# CONTROLSS_ADC4_CFG_CONTROLSS_ADC4_CFG register map
Vendor: Texas Instruments
Peripheral module from a debugger description file (folder AM263).
Registers are 16-bit, read-write, reset values left out (the file's numbers can be read two ways) unless marked. A register's access mark holds for its fields unless they carry their own. Offsets are as the file gives them; lines under a group give offsets from that group; [hi:lo] are bit positions; {n}, {i} and the like mark numbered series; 'fields as' and 'values as' point back to an identical list; <NAME> marks a mode.

## CONTROLSS_ADC4_CFG_CONTROLSS_ADC4_CFG
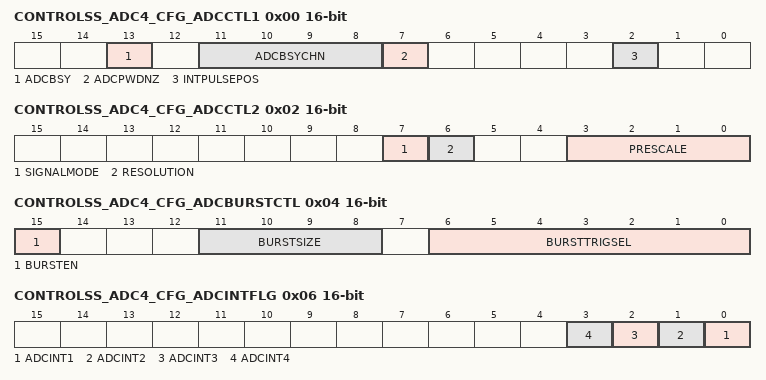
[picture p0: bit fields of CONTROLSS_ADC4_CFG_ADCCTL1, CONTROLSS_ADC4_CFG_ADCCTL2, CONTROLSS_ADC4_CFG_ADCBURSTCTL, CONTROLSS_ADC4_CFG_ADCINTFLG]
0x00 CONTROLSS_ADC4_CFG_ADCCTL1 access per field
  [13] ADCBSY ro — ADC Busy. Set when ADC SOC is generated, cleared by hardware four ADC clocks after negative edge of S/H pulse. Used by the ADC state machine to determine if ADC is available to sample. 0 ADC is available to sample next channel 1 ADC is busy and cannot sample another channel
  [11:8] ADCBSYCHN ro — ADC Busy Channel. Set when an ADC Start of Conversion (SOC) is generated. When ADCBSY=0: holds the value of the last converted SOC When ADCBSY=1: reflects the SOC currently being processed 0h SOC0 is currently processing or was last SOC converted 1h SOC1 is currently processing or was last SOC converted 2h SOC2 is currently processing or was last SOC converted 3h SOC3 is currently processing or was last SOC converted 4h SOC4 is currently processing or was last SOC converted 5h SOC5 is currently processing or was last SOC converted 6h SOC6 is currently processing or was last SOC converted 7h SOC7 is currently processing or was last SOC converted 8h SOC8 is currently processing or was last SOC converted 9h SOC9 is currently processing or was last SOC converted Ah SOC10 is currently processing or was last SOC converted Bh SOC11 is currently processing or was last SOC converted Ch SOC12 is currently processing or was last SOC converted Dh SOC13 is currently processing or was last SOC converted Eh SOC14 is currently processing or was last SOC converted Fh SOC15 is currently processing or was last SOC converted
  [7] ADCPWDNZ rw — ADC Power Down (active low). This bit controls the power up and power down of all the analog circuitry inside the analog core. 0 All analog circuitry inside the core is powered down 1 All analog circuitry inside the core is powered up
  [2] INTPULSEPOS rw — ADC Interrupt Pulse Position. 0 Interrupt pulse generation occurs when ADC begins conversion (at the end of the acquisition window) plus a number of SYSCLK cycles as specified in the ADCINTCYCLE.OFFSET register. 1 Interrupt pulse generation occurs at the end of the conversion, 1 cycle prior to the ADC result latching into its result register
0x02 CONTROLSS_ADC4_CFG_ADCCTL2
  [7] SIGNALMODE — SOC Signaling Mode. Selects the input mode of the converter. Use the AdcSetMode function to change the signal mode. 0 Single-ended 1 Differential
  [6] RESOLUTION — SOC Conversion Resolution. Selects the resolution of the converter. Use the AdcSetMode function to change the resolution. 0 12-bit resolution 1 16-bit resolution
  [3:0] PRESCALE — ADC Clock Prescaler. 0000 ADCCLK = Input Clock / 1.0 0001 Invalid 0010 ADCCLK = Input Clock / 2.0 0011 ADCCLK = Input Clock / 2.5 0100 ADCCLK = Input Clock / 3.0 0101 ADCCLK = Input Clock / 3.5 0110 ADCCLK = Input Clock / 4.0 0111 ADCCLK = Input Clock / 4.5 1000 ADCCLK = Input Clock / 5.0 1001 ADCCLK = Input Clock / 5.5 1010 ADCCLK = Input Clock / 6.0 1011 ADCCLK = Input Clock / 6.5 1100 ADCCLK = Input Clock / 7.0 1101 ADCCLK = Input Clock / 7.5 1110 ADCCLK = Input Clock / 8.0 1111 ADCCLK = Input Clock / 8.5
0x04 CONTROLSS_ADC4_CFG_ADCBURSTCTL
  [15] BURSTEN — SOC Burst Mode Enable. This bit enables the SOC Burst Mode of operation. 0 Burst mode is disabled. 1 Burst mode is enabled.
  [11:8] BURSTSIZE — SOC Burst Size Select. This bit field determines how many SOCs are converted when a burst conversion sequence is started. The first SOC converted is defined by the round robin pointer, which is advanced as each SOC is converted. 0h 1 SOC converted 1h 2 SOCs converted 2h 3 SOCs converted 3h 4 SOCs converted 4h 5 SOCs converted 5h 6 SOCs converted 6h 7 SOCs converted 7h 8 SOCs converted 8h 9 SOCs converted 9h 10 SOCs converted Ah 11 SOCs converted Bh 12 SOCs converted Ch 13 SOCs converted Dh 14 SOCs converted Eh 15 SOCs converted Fh 16 SOCs converted
  [6:0] BURSTTRIGSEL — SOC Burst Trigger Source Select. Configures which trigger will start a burst conversion sequence. 00h - 7Fh: See AM602 spec. for trigger defintion
0x06 CONTROLSS_ADC4_CFG_ADCINTFLG ro
  [n-1] ADCINT{n} (n=1..4) — ADC Interrupt {n} Flag. Reading these flags indicates if the associated ADCINT pulse was generated since the last clear. 0 No ADC interrupt pulse generated 1 ADC interrupt pulse generated If the ADC interrupt is placed in continue to interrupt mode (INTSELxNy register) then further interrupt pulses are generated whenever a selected EOC event occurs even if the flag bit is set. If the continuous mode is not enabled, then no further interrupt pulses are generated until the user clears this flag bit using the ADCINTFLGCLR register. Rather, an ADC interrupt overflow event occurs in the ADCINTOVF register.
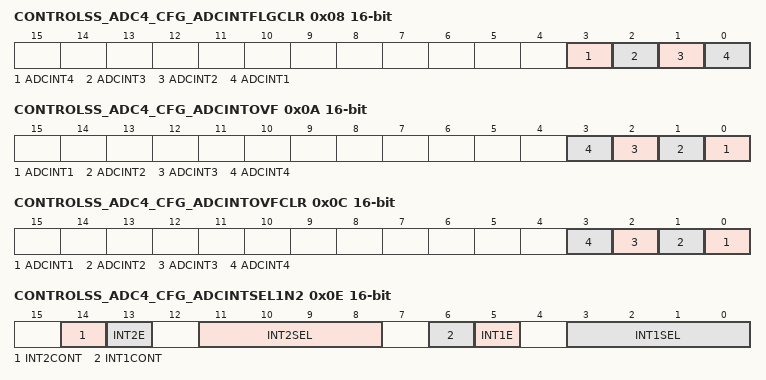
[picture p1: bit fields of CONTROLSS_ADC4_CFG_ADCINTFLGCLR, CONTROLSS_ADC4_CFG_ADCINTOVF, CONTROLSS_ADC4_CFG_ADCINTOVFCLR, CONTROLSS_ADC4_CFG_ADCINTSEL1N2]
0x08 CONTROLSS_ADC4_CFG_ADCINTFLGCLR access not given
  [3] ADCINT4 — ADC Interrupt 4 Flag Clear. Reads return 0. 0 No action 1 Clears ADCINT4 and ADCINT4RESULT flags in the ADCINTFLG register. If software sets the clear bit on the same cycle that hardware is trying to set the flag bit, then hardware has priority and the overflow bit will not be set (access RW RRETURNS0S)
  [2] ADCINT3 — ADC Interrupt 3 Flag Clear. Reads return 0. 0 No action 1 Clears ADCINT3 and ADCINT3RESULT flags in the ADCINTFLG register. If software sets the clear bit on the same cycle that hardware is trying to set the flag bit, then hardware has priority and the overflow bit will not be set (access RW RRETURNS0S)
  [1] ADCINT2 — ADC Interrupt 2 Flag Clear. Reads return 0. 0 No action 1 Clears ADCINT2 and ADCINT2RESULT flags in the ADCINTFLG register. . If software sets the clear bit on the same cycle that hardware is trying to set the flag bit, then hardware has priority and the overflow bit will not be set (access RW RRETURNS0S)
  [0] ADCINT1 — ADC Interrupt 1 Flag Clear. Reads return 0. 0 No action 1 Clears ADCINT1 and ADCINT1RESULT flags in the ADCINTFLG register. If software sets the clear bit on the same cycle that hardware is trying to set the flag bit, then hardware has priority and the overflow bit will not be set (access RW RRETURNS0S)
0x0A CONTROLSS_ADC4_CFG_ADCINTOVF ro
  [n-1] ADCINT{n} (n=1..4) — ADC Interrupt {n} Overflow Flags Indicates if an overflow occurred when generating ADCINT pulses. If the respective ADCINTFLG bit is set and a selected additional EOC trigger is generated, then an overflow condition occurs. 0 No ADC interrupt overflow event detected. 1 ADC Interrupt overflow event detected. The overflow bit does not care about the continuous mode bit state. An overflow condition is generated irrespective of this mode selection.
0x0C CONTROLSS_ADC4_CFG_ADCINTOVFCLR access not given
  [n-1] ADCINT{n} (n=1..4) — ADC Interrupt {n} Overflow Clear Bits 0 No action. 1 Clears the respective overflow bit in the ADCINTOVF register. If software tries to set this bit on the same clock cycle that hardware tries to set the overflow bit in the ADCINTOVF register, then hardware has priority and the ADCINTOVF bit will be set. (access RW RRETURNS0S)
0x0E CONTROLSS_ADC4_CFG_ADCINTSEL1N2
  [14] INT2CONT — ADCINT2 Continue to Interrupt Mode 0 No further ADCINT2 pulses are generated until ADCINT2 flag (in ADCINTFLG register) is cleared by user. 1 ADCINT2 pulses are generated whenever an EOC pulse is generated irrespective of whether the flag bit is cleared or not.
  [13] INT2E — ADCINT2 Interrupt Enable 0 ADCINT2 is disabled 1 ADCINT2 is enabled
  [11:8] INT2SEL — ADCINT2 EOC Source Select 0h EOC0 is trigger for ADCINT2 1h EOC1 is trigger for ADCINT2 2h EOC2 is trigger for ADCINT2 3h EOC3 is trigger for ADCINT2 4h EOC4 is trigger for ADCINT2 5h EOC5 is trigger for ADCINT2 6h EOC6 is trigger for ADCINT2 7h EOC7 is trigger for ADCINT2 8h EOC8 is trigger for ADCINT2 9h EOC9 is trigger for ADCINT2 Ah EOC10 is trigger for ADCINT2 Bh EOC11 is trigger for ADCINT2 Ch EOC12 is trigger for ADCINT2 Dh EOC13 is trigger for ADCINT2 Eh EOC14 is trigger for ADCINT2 Fh EOC15 is trigger for ADCINT2
  [6] INT1CONT — ADCINT1 Continue to Interrupt Mode 0 No further ADCINT1 pulses are generated until ADCINT1 flag (in ADCINTFLG register) is cleared by user. 1 ADCINT1 pulses are generated whenever an EOC pulse is generated irrespective of whether the flag bit is cleared or not.
  [5] INT1E — ADCINT1 Interrupt Enable 0 ADCINT1 is disabled 1 ADCINT1 is enabled
  [3:0] INT1SEL — ADCINT1 EOC Source Select 0h EOC0 is trigger for ADCINT1 1h EOC1 is trigger for ADCINT1 2h EOC2 is trigger for ADCINT1 3h EOC3 is trigger for ADCINT1 4h EOC4 is trigger for ADCINT1 5h EOC5 is trigger for ADCINT1 6h EOC6 is trigger for ADCINT1 7h EOC7 is trigger for ADCINT1 8h EOC8 is trigger for ADCINT1 9h EOC9 is trigger for ADCINT1 Ah EOC10 is trigger for ADCINT1 Bh EOC11 is trigger for ADCINT1 Ch EOC12 is trigger for ADCINT1 Dh EOC13 is trigger for ADCINT1 Eh EOC14 is trigger for ADCINT1 Fh EOC15 is trigger for ADCINT1
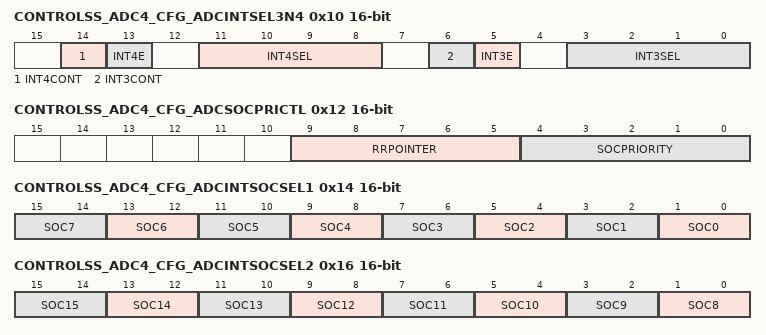
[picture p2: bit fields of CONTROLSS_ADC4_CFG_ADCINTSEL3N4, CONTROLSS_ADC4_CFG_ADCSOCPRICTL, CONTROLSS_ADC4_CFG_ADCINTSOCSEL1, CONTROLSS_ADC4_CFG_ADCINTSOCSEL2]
0x10 CONTROLSS_ADC4_CFG_ADCINTSEL3N4
  [14] INT4CONT — ADCINT4 Continue to Interrupt Mode 0 No further ADCINT4 pulses are generated until ADCINT4 flag (in ADCINTFLG register) is cleared by user. 1 ADCINT4 pulses are generated whenever an EOC pulse is generated irrespective of whether the flag bit is cleared or not.
  [13] INT4E — ADCINT4 Interrupt Enable 0 ADCINT4 is disabled 1 ADCINT4 is enabled
  [11:8] INT4SEL — ADCINT4 EOC Source Select 0h EOC0 is trigger for ADCINT4 1h EOC1 is trigger for ADCINT4 2h EOC2 is trigger for ADCINT4 3h EOC3 is trigger for ADCINT4 4h EOC4 is trigger for ADCINT4 5h EOC5 is trigger for ADCINT4 6h EOC6 is trigger for ADCINT4 7h EOC7 is trigger for ADCINT4 8h EOC8 is trigger for ADCINT4 9h EOC9 is trigger for ADCINT4 Ah EOC10 is trigger for ADCINT4 Bh EOC11 is trigger for ADCINT4 Ch EOC12 is trigger for ADCINT4 Dh EOC13 is trigger for ADCINT4 Eh EOC14 is trigger for ADCINT4 Fh EOC15 is trigger for ADCINT4
  [6] INT3CONT — ADCINT3 Continue to Interrupt Mode 0 No further ADCINT3 pulses are generated until ADCINT3 flag (in ADCINTFLG register) is cleared by user. 1 ADCINT3 pulses are generated whenever an EOC pulse is generated irrespective of whether the flag bit is cleared or not.
  [5] INT3E — ADCINT3 Interrupt Enable 0 ADCINT3 is disabled 1 ADCINT3 is enabled
  [3:0] INT3SEL — ADCINT3 EOC Source Select 0h EOC0 is trigger for ADCINT3 1h EOC1 is trigger for ADCINT3 2h EOC2 is trigger for ADCINT3 3h EOC3 is trigger for ADCINT3 4h EOC4 is trigger for ADCINT3 5h EOC5 is trigger for ADCINT3 6h EOC6 is trigger for ADCINT3 7h EOC7 is trigger for ADCINT3 8h EOC8 is trigger for ADCINT3 9h EOC9 is trigger for ADCINT3 Ah EOC10 is trigger for ADCINT3 Bh EOC11 is trigger for ADCINT3 Ch EOC12 is trigger for ADCINT3 Dh EOC13 is trigger for ADCINT3 Eh EOC14 is trigger for ADCINT3 Fh EOC15 is trigger for ADCINT3
0x12 CONTROLSS_ADC4_CFG_ADCSOCPRICTL access per field
  [9:5] RRPOINTER ro — Round Robin Pointer. Holds the value of the last converted round robin SOCx to be used by the round robin scheme to determine order of conversions. 00h SOC0 was last round robin SOC to convert, SOC1 is highest round robin priority. 01h SOC1 was last round robin SOC to convert, SOC2 is highest round robin priority. 02h SOC2 was last round robin SOC to convert, SOC3 is highest round robin priority. 03h SOC3 was last round robin SOC to convert, SOC4 is highest round robin priority. 04h SOC4 was last round robin SOC to convert, SOC5 is highest round robin priority. 05h SOC5 was last round robin SOC to convert, SOC6 is highest round robin priority. 06h SOC6 was last round robin SOC to convert, SOC7 is highest round robin priority. 07h SOC7 was last round robin SOC to convert, SOC8 is highest round robin priority. 08h SOC8 was last round robin SOC to convert, SOC9 is highest round robin priority. 09h SOC9 was last round robin SOC to convert, SOC10 is highest round robin priority. 0Ah SOC10 was last round robin SOC to convert, SOC11 is highest round robin priority. 0Bh SOC11 was last round robin SOC to convert, SOC12 is highest round robin priority. 0Ch SOC12 was last round robin SOC to convert, SOC13 is highest round robin priority. 0Dh SOC13 was last round robin SOC to convert, SOC14 is highest round robin priority. 0Eh SOC14 was last round robin SOC to convert, SOC15 is highest round robin priority. 0Fh SOC15 was last round robin SOC to convert, SOC0 is highest round robin priority. 10h Reset value to indicate no SOC has been converted. SOC0 is highest round robin priority. Set to this value when the device is reset, when the ADCCTL1.RESET bit is set, or when the ADCSOCPRICTL register is written. In the latter case, if a conversion is currently in progress, it will complete and then the new priority will take effect. Others Invalid value.
  [4:0] SOCPRIORITY rw — SOC Priority Determines the cutoff point for priority mode and round robin arbitration for SOCx 00h SOC priority is handled in round robin mode for all channels. 01h SOC0 is high priority, rest of channels are in round robin mode. 02h SOC0-SOC1 are high priority, SOC2-SOC15 are in round robin mode. 03h SOC0-SOC2 are high priority, SOC3-SOC15 are in round robin mode. 04h SOC0-SOC3 are high priority, SOC4-SOC15 are in round robin mode. 05h SOC0-SOC4 are high priority, SOC5-SOC15 are in round robin mode. 06h SOC0-SOC5 are high priority, SOC6-SOC15 are in round robin mode. 07h SOC0-SOC6 are high priority, SOC7-SOC15 are in round robin mode. 08h SOC0-SOC7 are high priority, SOC8-SOC15 are in round robin mode. 09h SOC0-SOC8 are high priority, SOC9-SOC15 are in round robin mode. 0Ah SOC0-SOC9 are high priority, SOC10-SOC15 are in round robin mode. 0Bh SOC0-SOC10 are high priority, SOC11-SOC15 are in round robin mode. 0Ch SOC0-SOC11 are high priority, SOC12-SOC15 are in round robin mode. 0Dh SOC0-SOC12 are high priority, SOC13-SOC15 are in round robin mode. 0Eh SOC0-SOC13 are high priority, SOC14-SOC15 are in round robin mode. 0Fh SOC0-SOC14 are high priority, SOC15 is in round robin mode. 10h All SOCs are in high priority mode, arbitrated by SOC number. Others Invalid selection.
0x14 CONTROLSS_ADC4_CFG_ADCINTSOCSEL1
  [2n+1:2n] SOC{n} (n=0..7) — SOC{n} ADC Interrupt Trigger Select. Selects which, if any, ADCINT triggers SOC{n}. The trigger selected in this field is in addition to the TRIGSEL field in the ADCSOCxCTL register. 00 No ADCINT will trigger SOC{n}. TRIGSEL field alone determines SOC0 trigger. 01 ADCINT1 will trigger SOC{n}. 10 ADCINT2 will trigger SOC{n}. 11 Invalid selection.
0x16 CONTROLSS_ADC4_CFG_ADCINTSOCSEL2
  [2n-15:2n-16] SOC{n} (n=8..15) — SOC{n} ADC Interrupt Trigger Select. Selects which, if any, ADCINT triggers SOC{n}. The trigger selected in this field is in addition to the TRIGSEL field in the ADCSOCxCTL register. 00 No ADCINT will trigger SOC{n}. TRIGSEL field alone determines SOC0 trigger. 01 ADCINT1 will trigger SOC{n}. 10 ADCINT2 will trigger SOC{n}. 11 Invalid selection.
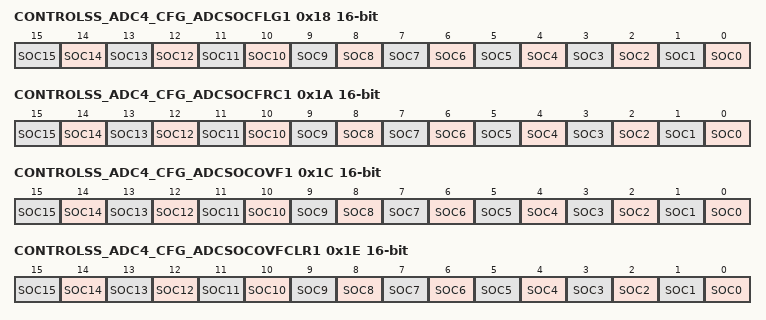
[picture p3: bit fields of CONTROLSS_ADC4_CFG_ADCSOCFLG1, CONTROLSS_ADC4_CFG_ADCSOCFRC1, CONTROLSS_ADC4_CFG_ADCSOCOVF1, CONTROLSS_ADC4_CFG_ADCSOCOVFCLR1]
0x18 CONTROLSS_ADC4_CFG_ADCSOCFLG1 ro
  [n] SOC{n} (n=0..15) — SOC{n} Start of Conversion Flag. Indicates the state of SOC{n} conversions. 0 No sample pending for SOC{n}. 1 Trigger has been received and sample is pending for SOC{n}. This bit will be automatically cleared when the SOC{n} conversion is started. If contention exists where this bit receives both a request to set and a request to clear on the same cycle, regardless of the source of either, this bit will be set and the request to clear will be ignored. In this case the overflow bit in the ADCSOCOVF1 register will not be affected regardless of whether this bit was previously set or not.
0x1A CONTROLSS_ADC4_CFG_ADCSOCFRC1 access not given
  [n] SOC{n} (n=0..15) — SOC{n} Force Start of Conversion Bit. Writing a 1 will force to 1 the SOC{n} flag in the ADCSOCFLG1 register. This can be used to initiate a software initiated conversion. Writes of 0 are ignored. This bit will always read as a 0. 0 No action. 1 Force SOC{n} flag bit to 1. This will cause a conversion to start once priority is given to SOC{n}. If software tries to set this bit on the same clock cycle that hardware tries to clear the SOC{n} bit in the ADCSOCFLG1 register, then software has priority and the ADCSOCFLG1 bit will be set. In this case the overflow bit in the ADCSOCOVF1 register will not be affected regardless of whether the ADCSOCFLG1 bit was previously set or not. (access RW RRETURNS0S)
0x1C CONTROLSS_ADC4_CFG_ADCSOCOVF1 ro
  [n] SOC{n} (n=0..15) — SOC{n} Start of Conversion Overflow Flag. Indicates an SOC{n} event was generated in hardware while an existing SOC{n} event was already pending. 0 No SOC{n} event overflow. 1 SOC{n} event overflow. An overflow condition does not stop SOC{n} events from being processed. It simply is an indication that a hardware trigger was missed. A write to the ADCSOCFRC1 register does not affect this bit.
0x1E CONTROLSS_ADC4_CFG_ADCSOCOVFCLR1 access not given
  [n] SOC{n} (n=0..15) — SOC{n} Clear Start of Conversion Overflow Bit. Writing a 1 will clear the SOC{n} overflow flag in the ADCSOCOVF1 register. Writes of 0 are ignored. Reads will always return a 0. 0 No action. 1 Clear SOC{n} overflow flag. If software tries to set this bit on the same clock cycle that hardware tries to set the overflow bit in the ADCSOCOVF1 register, then hardware has priority and the ADCSOCOVF1 bit will be set.. (access RW RRETURNS0S)
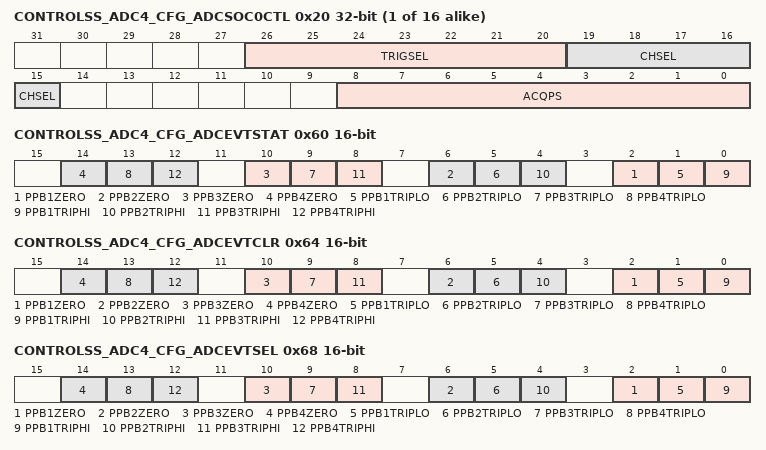
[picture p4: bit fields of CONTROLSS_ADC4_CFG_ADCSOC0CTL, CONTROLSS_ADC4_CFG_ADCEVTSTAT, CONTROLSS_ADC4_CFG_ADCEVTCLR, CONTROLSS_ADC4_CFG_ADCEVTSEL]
{0x20+4i} CONTROLSS_ADC4_CFG_ADCSOC{i}CTL 32-bit (i=0..15)
  [26:20] TRIGSEL — SOC{i} Trigger Source Select. Along with the SOC{i} field in the ADCINTSOCSEL1 register, this bit field configures which trigger will set the SOC{i} flag in the ADCSOCFLG1 register to initiate a conversion to start once priority is given to it. 00h - 7Fh: See AM602 Spec. for trigger defintion
  [19:15] CHSEL — SOC{i} Channel Select. Selects the channel to be converted when SOC{i} is received by the ADC. 00h ADCIN0 01h ADCIN1 02h ADCIN2 03h ADCIN3 ... 1Dh ADCIN29 1Eh ADCIN30 1Fh ADCIN31
  [8:0] ACQPS — SOC{i} Acquisition Prescale. Controls the sample and hold window for this SOC. The configured acquisition time must be at least as long as one ADCCLK cycle for correct ADC operation. The device datasheet will also specify a minimum sample and hold window duration. 000h Sample window is 1 system clock cycle wide 001h Sample window is 2 system clock cycles wide 002h Sample window is 3 system clock cycles wide ... 1FFh Sample window is 512 system clock cycles wide
0x60 CONTROLSS_ADC4_CFG_ADCEVTSTAT ro
  [4n-2] PPB{n}ZERO (n=1..4) — Post Processing Block {n} Zero Crossing Flag. When set indicates the ADCPPB{n}RESULT register has changed sign. This bit is gated by EOC signal.
  [4n-3] PPB{n}TRIPLO (n=1..4) — Post Processing Block {n} Trip Low Flag. When set indicates a digital compare trip low event has occurred.
  [4n-4] PPB{n}TRIPHI (n=1..4) — Post Processing Block {n} Trip High Flag. When set indicates a digital compare trip high event has occurred.
0x64 CONTROLSS_ADC4_CFG_ADCEVTCLR access not given
  [4n-2] PPB{n}ZERO (n=1..4) — Post Processing Block {n} Zero Crossing Clear. Clears the corresponding zero crossing flag in the ADCEVTSTAT register. (access RW RRETURNS0S)
  [4n-3] PPB{n}TRIPLO (n=1..4) — Post Processing Block {n} Trip Low Clear. Clears the corresponding trip low flag in the ADCEVTSTAT register. (access RW RRETURNS0S)
  [4n-4] PPB{n}TRIPHI (n=1..4) — Post Processing Block {n} Trip High Clear. Clears the corresponding trip high flag in the ADCEVTSTAT register. (access RW RRETURNS0S)
0x68 CONTROLSS_ADC4_CFG_ADCEVTSEL
  [4n-2] PPB{n}ZERO (n=1..4) — Post Processing Block {n} Zero Crossing Event Enable. Setting this bit allows the corresponding rising zero crossing flag to activate the event signal to the PWM blocks. The flag must be cleared before it can produce additional events to the PWM blocks.
  [4n-3] PPB{n}TRIPLO (n=1..4) — Post Processing Block {n} Trip Low Event Enable. Setting this bit allows the corresponding rising trip low flag to activate the event signal to the PWM blocks. The flag must be cleared before it can produce additional events to the PWM blocks.
  [4n-4] PPB{n}TRIPHI (n=1..4) — Post Processing Block {n} Trip High Event Enable. Setting this bit allows the corresponding rising trip high flag to activate the event signal to the PWM blocks. The flag must be cleared before it can produce additional events to the PWM blocks.
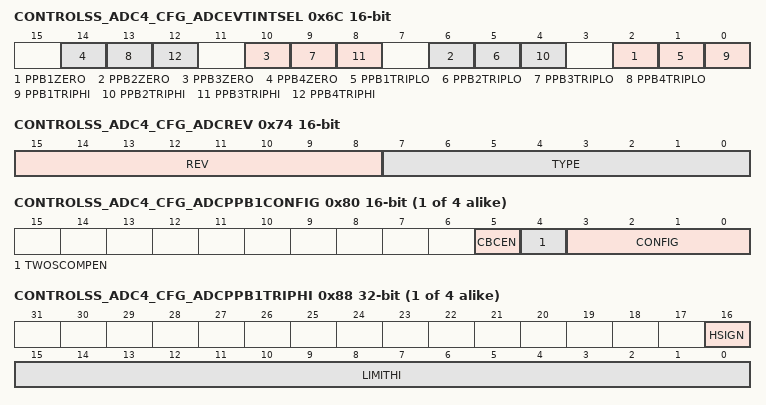
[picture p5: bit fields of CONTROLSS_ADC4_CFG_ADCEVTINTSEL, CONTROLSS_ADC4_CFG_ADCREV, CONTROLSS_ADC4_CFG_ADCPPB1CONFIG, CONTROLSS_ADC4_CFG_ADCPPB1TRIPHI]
0x6C CONTROLSS_ADC4_CFG_ADCEVTINTSEL
  [4n-2] PPB{n}ZERO (n=1..4) — Post Processing Block {n} Zero Crossing Interrupt Enable. Setting this bit allows the corresponding rising zero crossing flag to activate the event interrupt signal to the PIE. The flag must be cleared before it can produce additional interrupts to the PIE.
  [4n-3] PPB{n}TRIPLO (n=1..4) — Post Processing Block {n} Trip Low Interrupt Enable. Setting this bit allows the corresponding rising trip low flag to activate the event interrupt signal to the PIE. The flag must be cleared before it can produce additional interrupts to the PIE.
  [4n-4] PPB{n}TRIPHI (n=1..4) — Post Processing Block {n} Trip High Interrupt Enable. Setting this bit allows the corresponding rising trip high flag to activate the event interrupt signal to the PIE. The flag must be cleared before it can produce additional interrupts to the PIE.
0x70 CONTROLSS_ADC4_CFG_ADCOSDETECT
  [2:0] DETECTCFG — ADC Opens and Shorts Detect Configuration. This bit field defines the open/shorts detection circuit state. 0h Open/Shorts detection circuit is disabled. 1h Open/Shorts detection circuit is enabled at zero scale. 2h Open/Shorts detection circuit is enabled at full scale. 3h Open/Shorts detection circuit is enabled at (nominal) 5/12 scale. 4h Open/Shorts detection circuit is enabled at (nominal) 7/12 scale. 5h Open/Shorts detection circuit is enabled with a (nominal) 5K pulldown to VSSA. 6h Open/Shorts detection circuit is enabled with a (nominal) 5K pullup to VDDA. 7h Open/Shorts detection circuit is enabled with a (nominal) 7K pulldown to VSSA.
0x72 CONTROLSS_ADC4_CFG_ADCCOUNTER ro
  [11:0] FREECOUNT — ADC Free Running Counter Value. This bit field reflects the status of the free running ADC counter.
0x74 CONTROLSS_ADC4_CFG_ADCREV ro
  [15:8] REV — ADC Revision. To allow documentation of differences between revisions. First version is labeled as 00h.
  [7:0] TYPE — ADC Type. Always set to 5 for this ADC.
0x76 CONTROLSS_ADC4_CFG_ADCOFFTRIM
  [7:0] OFFTRIM — ADC Offset Trim Adjusts the conversion results of the converter up or down to account for offset error in the ADC. A factory trim setting will be loaded during device boot. Offset can be corrected in the range of +7 to -8 LSBs. Value is 16*Offset in 8-bit 2's complement: 7 LSB (16*7) = 112 6 LSB (16*6) = 96 5 LSB (16*5) = 80 4 LSB (16*4) = 64 3 LSB (16*3) = 48 2 LSB (16*2) = 32 1 LSB (16*1) = 16 0 LSB (16*0) = 0 -1 LSB (16*(-1)) = 240 : : -7LSB(16*(-7)) = 144
0x7C CONTROLSS_ADC4_CFG_ADCCONFIG 32-bit
  [31:0] CONFIG — ADC Configuration. This bit field is used for TI internal testing/debugging.
{0x70+0x10*i} CONTROLSS_ADC4_CFG_ADCPPB{i}CONFIG (i=1..4)
  [5] CBCEN — ADC Post Processing Block Cycle By Cycle Enable. When set, this bit enables the post conversion hardware processing circuit to automatically clear the ADCEVTSTAT on a conversion if the event condition is no longer present.
  [4] TWOSCOMPEN — ADC Post Processing Block {i} Two's Complement Enable. When set this bit enables the post conversion hardware processing circuit that performs a two's complement on the output of the offset/reference subtraction unit before storing the result in the ADCPPB{i}RESULT register. 0 ADCPPB{i}RESULT = ADCRESULTx - ADCPPB{i}OFFREF 1 ADCPPB{i}RESULT = ADCPPB{i}OFFREF - ADCRESULTx
  [3:0] CONFIG — ADC Post Processing Block {i} Configuration. This bit field defines which SOC/EOC/RESULT is assocatied with this post processing block. 0000 SOC0/EOC0/RESULT0 is associated with post processing block {i} 0001 SOC1/EOC1/RESULT1 is associated with post processing block {i} 0010 SOC2/EOC2/RESULT2 is associated with post processing block {i} 0011 SOC3/EOC3/RESULT3 is associated with post processing block {i} 0100 SOC4/EOC4/RESULT4 is associated with post processing block {i} 0101 SOC5/EOC5/RESULT5 is associated with post processing block {i} 0110 SOC6/EOC6/RESULT6 is associated with post processing block {i} 0111 SOC7/EOC7/RESULT7 is associated with post processing block {i} 1000 SOC8/EOC8/RESULT8 is associated with post processing block {i} 1001 SOC9/EOC9/RESULT9 is associated with post processing block {i} 1010 SOC10/EOC10/RESULT10 is associated with post processing block {i} 1011 SOC11/EOC11/RESULT11 is associated with post processing block {i} 1100 SOC12/EOC12/RESULT12 is associated with post processing block {i} 1101 SOC13/EOC13/RESULT13 is associated with post processing block {i} 1110 SOC14/EOC14/RESULT14 is associated with post processing block {i} 1111 SOC15/EOC15/RESULT15 is associated with post processing block {i}
{0x72+0x10*i} CONTROLSS_ADC4_CFG_ADCPPB{i}STAMP ro (i=1..4)
  [11:0] DLYSTAMP — ADC Post Processing Block {i} Delay Time Stamp. When an SOC starts sampling the value contained in REQSTAMP is subtracted from the value in ADCCOUNTER.FREECOUNT and loaded into this bit field, thereby giving the number of system clock cycles delay between the SOC trigger and the actual start of the sample.
{0x74+0x10*i} CONTROLSS_ADC4_CFG_ADCPPB{i}OFFCAL (i=1..4)
  [9:0] OFFCAL — ADC Post Processing Block {i} Offset Correction. This bit field can be used to digitally remove any system level offset inherent in the ADCIN circuit. This 10-bit signed value is subtracted from the ADC output before being stored in the ADCRESULT register. 000h No change. The ADC output is stored directly into ADCRESULT. 001h ADC output - 1 is stored into ADCRESULT. 002h ADC output - 2 is stored into ADCRESULT. ... 200h ADC output + 512 is stored into ADCRESULT. ... 3FFh ADC output + 1 is stored into ADCRESULT. NOTE: In 16-bit mode, the subtraction will saturate at 0000h and FFFFh before being stored into the ADCRESULT register. In 12-bit mode, the subtraction will saturate at 0000h and 0FFFh before being stored into the ADCRESULT register.
{0x76+0x10*i} CONTROLSS_ADC4_CFG_ADCPPB{i}OFFREF (i=1..4)
  [15:0] OFFREF — ADC Post Processing Block {i} Offset Correction. This bit field can be used to either calculate the feedback error or convert a unipolar signal to bipolar by subtracting a reference value. This 16-bit unsigned value is subtracted from the ADCRESULT register before being passed through an optional two's complement function and stored in the ADCPPB{i}RESULT register. This subtraction is not saturated. 0000h No change. The ADCRESULT value is passed on. 0001h ADCRESULT - 1 is passed on. 0002h ADCRESULT - 2 is passed on. ... 8000h ADCRESULT - 32,768 is passed on. ... FFFFh ADCRESULT - 65,535 is passed on. NOTE: In 12-bit mode the size of this register does not change from 16-bits. It is the user's responsibility to ensure that only a 12-bit value is written to this register when in 12-bit mode.
{0x78+0x10*i} CONTROLSS_ADC4_CFG_ADCPPB{i}TRIPHI 32-bit (i=1..4)
  [16] HSIGN — High Limit Sign Bit. This is the sign bit (17th bit) to the LIMITHI bit field when in 16-bit ADC mode.
  [15:0] LIMITHI — ADC Post Processing Block {i} Trip High Limit. This value sets the digital comparator trip high limit. In 16-bit mode all 17 bits will be compared against the 17 bits of the PPBRESULT bit field of the ADCPPB{i}RESULT register. In 12-bit mode bits 12:0 will be compared against bits 12:0 of the PPBRESULT bit field of the ADCPPB{i}RESULT register.
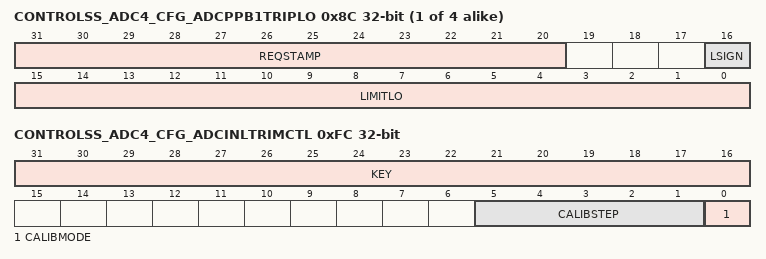
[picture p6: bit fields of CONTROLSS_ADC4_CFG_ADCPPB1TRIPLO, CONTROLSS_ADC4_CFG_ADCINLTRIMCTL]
{0x7C+0x10*i} CONTROLSS_ADC4_CFG_ADCPPB{i}TRIPLO 32-bit access per field (i=1..4)
  [31:20] REQSTAMP ro — ADC Post Processing Block {i} Request Time Stamp. When a trigger sets the associated SOC flag in the ADCSOCFLG1 register the value of ADCCOUNTER.FREECOUNT is loaded into this bit field.
  [16] LSIGN rw — Low Limit Sign Bit. This is the sign bit (17th bit) to the LIMITLO bit field when in 16-bit ADC mode.
  [15:0] LIMITLO rw — ADC Post Processing Block {i} Trip Low Limit. This value sets the digital comparator trip low limit. In 16-bit mode all 17 bits will be compared against the 17 bits of the PPBRESULT bit field of the ADCPPB{i}RESULT register. In 12-bit mode bits 12:0 will be compared against bits 12:0 of the PPBRSULT bit field of the ADCPPB{i}RESULT register.
0xDE CONTROLSS_ADC4_CFG_ADCINTCYCLE
  [15:0] DELAY — ADC Early Interrupt Generation Cycle Delay: Defines the delay from the fall edge of ADCSOC in terms of system clock cycles, for the interrupt to be generated.
{0xDC+4i} CONTROLSS_ADC4_CFG_ADCINLTRIM{i} 32-bit (i=1..6)
  [31:0] INLTRIM{32i-1}TO{32i-32} — ADC Linearity Trim Bits {32i-1}-{32i-32}. This register should not be modified unless specifically indicated by TI Errata or other documentation. Modifying the contents of this register could cause this module to operate outside of datasheet specifications.
0xFC CONTROLSS_ADC4_CFG_ADCINLTRIMCTL 32-bit
  [31:16] KEY — ADC Linearity Trim Control Write Key. Any write to this register must contain the value 0xA5A5 in these bit locations. If a write request attempts to load any other value into these bits, the write for the entire register is ignored. These bits always read back a zero.
  [5:1] CALIBSTEP — ADC Linearity Calibration Step. Defines which of the 24 steps of calibration is to be executed. Never set this bit field while the ADC SELFTRIM is in progress. The R-M-W operation could unintentionally set the CALIBMODE bit again.
  [0] CALIBMODE — ADC Linearity Calibration Mode.
